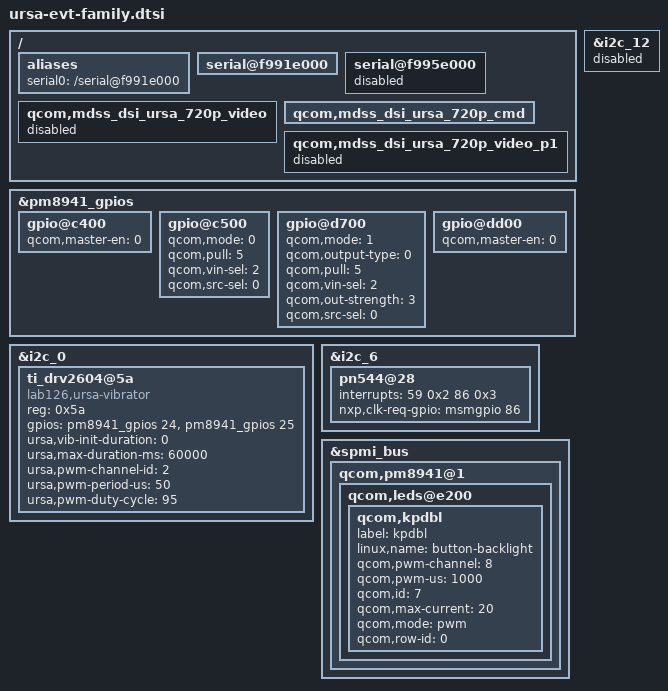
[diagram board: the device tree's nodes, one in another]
/* Copyright (c) 2013, The Linux Foundation. All rights reserved.
 *
 * This program is free software; you can redistribute it and/or modify
 * it under the terms of the GNU General Public License version 2 and
 * only version 2 as published by the Free Software Foundation.
 *
 * This program is distributed in the hope that it will be useful,
 * but WITHOUT ANY WARRANTY; without even the implied warranty of
 * MERCHANTABILITY or FITNESS FOR A PARTICULAR PURPOSE.  See the
 * GNU General Public License for more details.
 */

/* This device-tree include has properties common to Pre-EVT, EVT and P0.E
  * devices. Properties specific to a board go in board specific .dts.
  */

/ {
	aliases {
		serial0 = "/serial@f991e000";
	};

	serial@f991e000 {
		status = "ok";
	};

	serial@f995e000 {
		status = "disabled";
	};

	qcom,mdss_dsi_ursa_720p_video {
		status = "disabled";
	};

	qcom,mdss_dsi_ursa_720p_cmd {
		status = "ok";
	};

	qcom,mdss_dsi_ursa_720p_video_p1 {
		status = "disabled";
	};
};

/* I2C overrides */
&i2c_12 {
	status = "disabled";
};

&pm8941_gpios {
	gpio@c400 { /* GPIO 5 */
		qcom,master-en = <0>;	/* NC */
	};

	gpio@c500 { /* GPIO 6 HOME_BUTTON_OUT_N */
		qcom,mode = <0>;
		qcom,pull = <5>;
		qcom,vin-sel = <2>;
		qcom,src-sel = <0>;
	};

	gpio@d700 { /* GPIO 24 VIB_EN */
		qcom,mode = <1>;
		qcom,output-type = <0>;
		qcom,pull = <5>;
		qcom,vin-sel = <2>;
		qcom,out-strength = <3>;
		qcom,src-sel = <0>;
	};

	gpio@dd00 { /* GPIO 30 */
		qcom,master-en = <0>;	/* NC */
	};
};

&i2c_0 {
	ti_drv2604@5a { /* Ursa vibrator */
		compatible = "lab126,ursa-vibrator";
		reg = <0x5a>; /* i2c address */
		gpios = <&pm8941_gpios 24 0>, /* vib_enable pin is PMIC gpio 24 */
			<&pm8941_gpios 25 0>; /* IN/TRIG pin (vib_control) is PMIC gpio 25 */
		ursa,vib-init-duration = <0>; /* No boot vibration */
		ursa,max-duration-ms = <60000>; /* maxmimum allowed vibration duration is 60sec */
		ursa,pwm-channel-id = <2>; /* use pwm channel 3 */
		ursa,pwm-period-us = <50>; /* 20Khz */
		ursa,pwm-duty-cycle = <95>; /* 95% duty cycle */
	};
};

&i2c_6 {
		pn544@28 {
			interrupts = <59 0x2 86 0x3>;
			nxp,clk-req-gpio = <&msmgpio 86 0x00>;
		};
};

&spmi_bus {
	qcom,pm8941@1 {
		qcom,leds@e200 {
			status = "okay";
			qcom,kpdbl {
				label = "kpdbl";
				linux,name = "button-backlight";
				qcom,pwm-channel = <8>;
				qcom,pwm-us = <1000>;
				qcom,id = <7>;
				qcom,max-current = <20>;
				qcom,mode = "pwm";
				qcom,row-id = <0>;
			};
		};
	};
};
